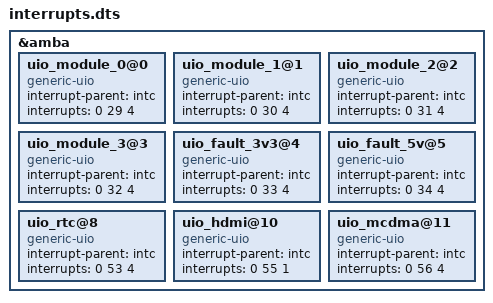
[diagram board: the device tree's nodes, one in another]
/dts-v1/;
/plugin/;

/ {
    fragment@0 {

        target = <&amba>;
        __overlay__ {

            uio_module_0@0 {
                compatible = "generic-uio";
                interrupt-parent = <&intc>;
                interrupts = <0 29 4>;
            };

            uio_module_1@1 {
                compatible = "generic-uio";
                interrupt-parent = <&intc>;
                interrupts = <0 30 4>;
            };

            uio_module_2@2 {
                compatible = "generic-uio";
                interrupt-parent = <&intc>;
                interrupts = <0 31 4>;
            };

            uio_module_3@3 {
                compatible = "generic-uio";
                interrupt-parent = <&intc>;
                interrupts = <0 32 4>;
            };

            uio_fault_3v3@4 {
                compatible = "generic-uio";
                interrupt-parent = <&intc>;
                interrupts = <0 33 4>;
            };

            uio_fault_5v@5 {
                compatible = "generic-uio";
                interrupt-parent = <&intc>;
                interrupts = <0 34 4>;
            };

            /*uio_fault_12v@6 {
                compatible = "generic-uio";
                interrupt-parent = <&intc>;
                interrupts = <0 35 4>;
            };

            uio_fault_ext_12v@7 {
                compatible = "generic-uio";
                interrupt-parent = <&intc>;
                interrupts = <0 52 4>;
            };*/

            uio_rtc@8 {
                compatible = "generic-uio";
                interrupt-parent = <&intc>;
                interrupts = <0 53 4>;
            };

            uio_hdmi@10 {
                compatible = "generic-uio";
                interrupt-parent = <&intc>;
                interrupts = <0 55 1>;
            };

            uio_mcdma@11 {
                compatible = "generic-uio";
                interrupt-parent = <&intc>;
                interrupts = <0 56 4>;
            };
        };
    };
};
